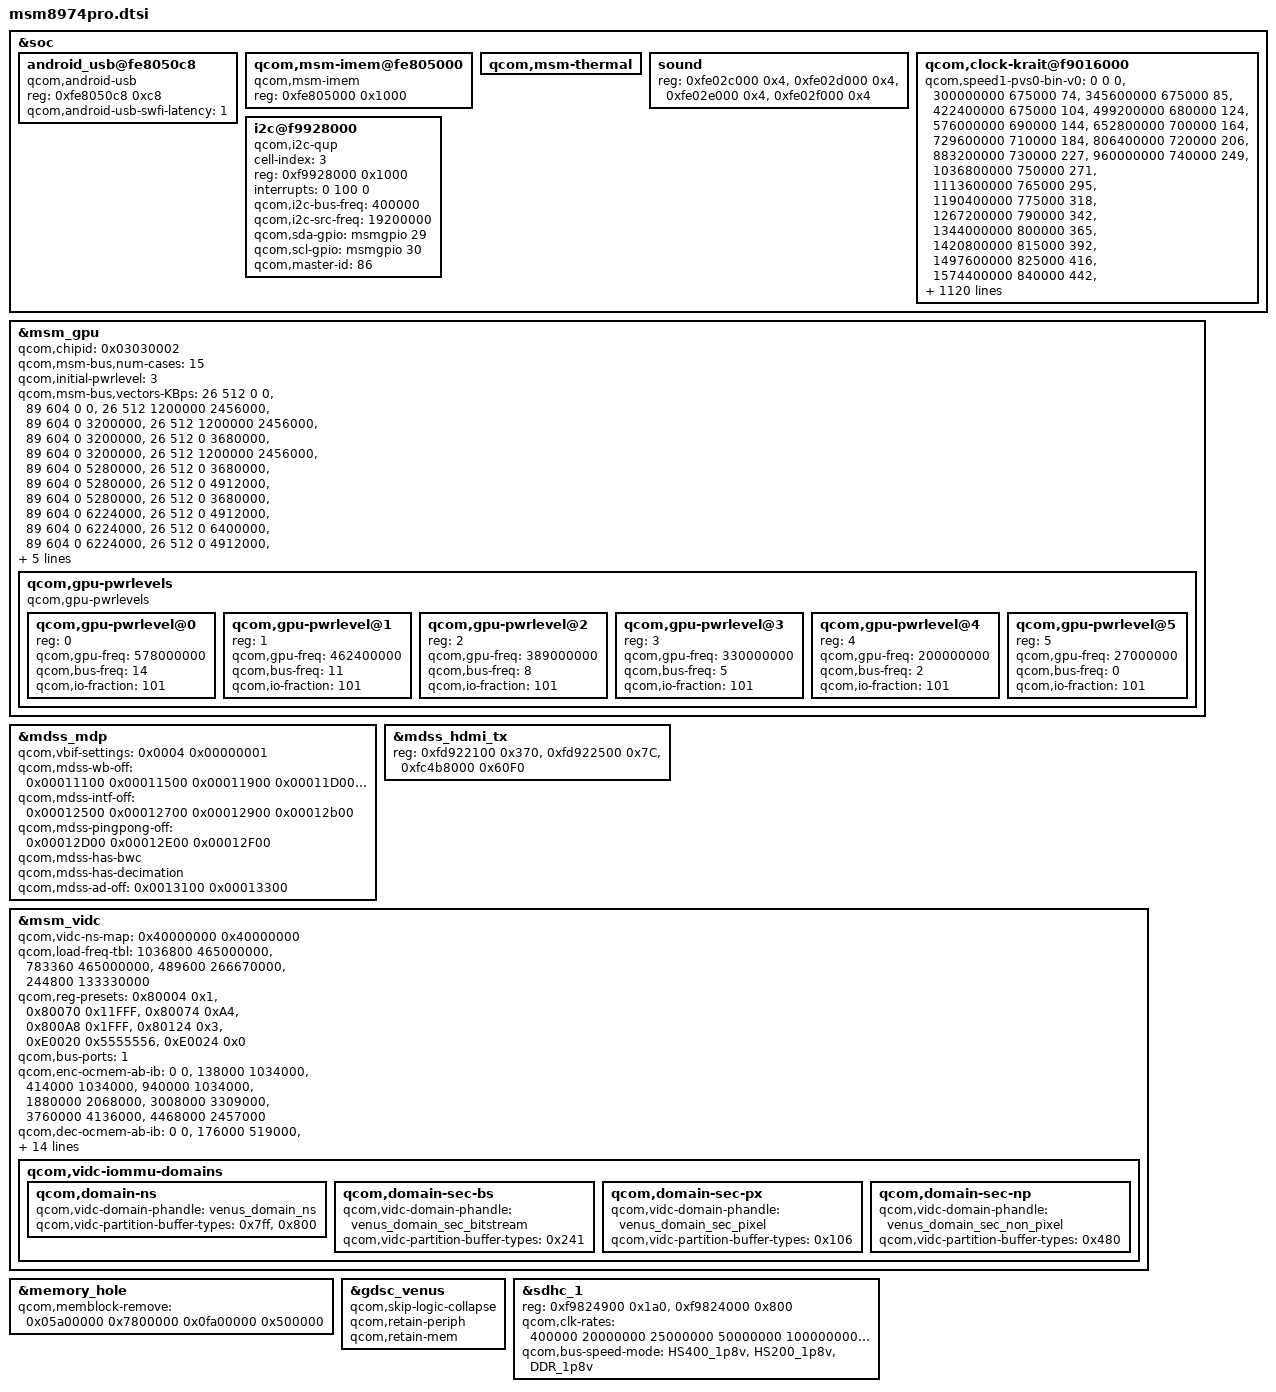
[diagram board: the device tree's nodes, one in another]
/* Copyright (c) 2013-2014, The Linux Foundation. All rights reserved.
 * Copyright (C) 2013 Sony Mobile Communications AB.
 *
 * This program is free software; you can redistribute it and/or modify
 * it under the terms of the GNU General Public License version 2 and
 * only version 2 as published by the Free Software Foundation.
 *
 * This program is distributed in the hope that it will be useful,
 * but WITHOUT ANY WARRANTY; without even the implied warranty of
 * MERCHANTABILITY or FITNESS FOR A PARTICULAR PURPOSE.  See the
 * GNU General Public License for more details.
 */

/*
 * As a general rule, only version-specific property overrides should be placed
 * inside this file. However, device definitions should be placed inside the
 * msm8974.dtsi file.
 */

/include/ "msm8974.dtsi"
/include/ "msm8974-v2-iommu.dtsi"
/include/ "msm8974-v2-iommu-domains.dtsi"
/include/ "msm8974pro-pm.dtsi"
/include/ "msm8974pro-ion.dtsi"

&soc {
	android_usb@fe8050c8 {
		compatible = "qcom,android-usb";
		reg = <0xfe8050c8 0xc8>;
		qcom,android-usb-swfi-latency = <1>;
	};

	qcom,msm-imem@fe805000 {
		compatible = "qcom,msm-imem";
		reg = <0xfe805000 0x1000>; /* Address and size of IMEM */
	};

	qcom,msm-thermal {
		/delete-property/ qcom,pmic-sw-mode-temp;
		/delete-property/ qcom,pmic-sw-mode-temp-hysteresis;
		/delete-property/ qcom,pmic-sw-mode-regs;
	};

	sound {
		reg = <0xfe02c000 0x4>,
		      <0xfe02d000 0x4>,
		      <0xfe02e000 0x4>,
		      <0xfe02f000 0x4>;
		reg-names = "lpaif_pri_mode_muxsel",
			    "lpaif_sec_mode_muxsel",
			    "lpaif_tert_mode_muxsel",
			    "lpaif_quat_mode_muxsel";
	};

	qcom,clock-krait@f9016000 {
		qcom,speed1-pvs0-bin-v0 =
			<          0       0    0 >,
			<  300000000  675000   74 >,
			<  345600000  675000   85 >,
			<  422400000  675000  104 >,
			<  499200000  680000  124 >,
			<  576000000  690000  144 >,
			<  652800000  700000  164 >,
			<  729600000  710000  184 >,
			<  806400000  720000  206 >,
			<  883200000  730000  227 >,
			<  960000000  740000  249 >,
			< 1036800000  750000  271 >,
			< 1113600000  765000  295 >,
			< 1190400000  775000  318 >,
			< 1267200000  790000  342 >,
			< 1344000000  800000  365 >,
			< 1420800000  815000  392 >,
			< 1497600000  825000  416 >,
			< 1574400000  840000  442 >,
			< 1651200000  855000  469 >,
			< 1728000000  870000  497 >,
			< 1804800000  885000  525 >,
			< 1881600000 900000  554 >,
			< 1958400000 915000  583 >,
			< 2035200000 930000  613 >,
			< 2112000000 945000  642 >,
			< 2150400000 960000  663 >,
			< 2188800000 960000  675 >,
			< 2265600000 975000  708 >;

		qcom,speed1-pvs1-bin-v0 =
			<          0       0    0 >,
			<  300000000  675000   74 >,
			<  345600000  675000   85 >,
			<  422400000  675000  104 >,
			<  499200000  675000  124 >,
			<  576000000  675000  144 >,
			<  652800000  685000  164 >,
			<  729600000  695000  184 >,
			<  806400000  705000  206 >,
			<  883200000  715000  227 >,
			<  960000000  725000  249 >,
			< 1036800000  735000  271 >,
			< 1113600000  750000  295 >,
			< 1190400000  760000  318 >,
			< 1267200000  770000  342 >,
			< 1344000000  785000  365 >,
			< 1420800000  795000  392 >,
			< 1497600000  805000  416 >,
			< 1574400000  820000  442 >,
			< 1651200000  835000  469 >,
			< 1728000000  850000  497 >,
			< 1804800000  865000  525 >,
			< 1881600000  880000  554 >,
			< 1958400000  895000  583 >,
			< 2035200000 905000  613 >,
			< 2112000000 920000  642 >,
			< 2150400000 935000  663 >,
			< 2188800000 935000  675 >,
			< 2265600000 950000  708 >;

		qcom,speed1-pvs2-bin-v0 =
			<          0       0    0 >,
			<  300000000  650000   74 >,
			<  345600000  650000   85 >,
			<  422400000  650000  104 >,
			<  499200000  650000  124 >,
			<  576000000  660000  144 >,
			<  652800000  670000  164 >,
			<  729600000  680000  184 >,
			<  806400000  690000  206 >,
			<  883200000  700000  227 >,
			<  960000000  710000  249 >,
			< 1036800000  720000  271 >,
			< 1113600000  730000  295 >,
			< 1190400000  740000  318 >,
			< 1267200000  750000  342 >,
			< 1344000000  765000  365 >,
			< 1420800000  775000  392 >,
			< 1497600000  785000  416 >,
			< 1574400000  800000  442 >,
			< 1651200000  815000  469 >,
			< 1728000000  830000  497 >,
			< 1804800000  845000  525 >,
			< 1881600000  855000  554 >,
			< 1958400000  870000  583 >,
			< 2035200000  880000  613 >,
			< 2112000000  895000  642 >,
			< 2150400000 910000  663 >,
			< 2188800000 910000  675 >,
			< 2265600000 925000  708 >;

		qcom,speed1-pvs3-bin-v0 =
			<          0       0    0 >,
			<  300000000  650000   74 >,
			<  345600000  650000   85 >,
			<  422400000  650000  104 >,
			<  499200000  650000  124 >,
			<  576000000  650000  144 >,
			<  652800000  655000  164 >,
			<  729600000  665000  184 >,
			<  806400000  675000  206 >,
			<  883200000  685000  227 >,
			<  960000000  695000  249 >,
			< 1036800000  705000  271 >,
			< 1113600000  715000  295 >,
			< 1190400000  725000  318 >,
			< 1267200000  735000  342 >,
			< 1344000000  750000  365 >,
			< 1420800000  760000  392 >,
			< 1497600000  770000  416 >,
			< 1574400000  785000  442 >,
			< 1651200000  800000  469 >,
			< 1728000000  810000  497 >,
			< 1804800000  825000  525 >,
			< 1881600000  835000  554 >,
			< 1958400000  845000  583 >,
			< 2035200000  860000  613 >,
			< 2112000000  870000  642 >,
			< 2150400000  885000  663 >,
			< 2188800000  885000  675 >,
			< 2265600000 900000  708 >;

		qcom,speed1-pvs4-bin-v0 =
			<          0       0    0 >,
			<  300000000  650000   74 >,
			<  345600000  650000   85 >,
			<  422400000  650000  104 >,
			<  499200000  650000  124 >,
			<  576000000  650000  144 >,
			<  652800000  650000  164 >,
			<  729600000  655000  184 >,
			<  806400000  665000  206 >,
			<  883200000  675000  227 >,
			<  960000000  685000  249 >,
			< 1036800000  695000  271 >,
			< 1113600000  705000  295 >,
			< 1190400000  715000  318 >,
			< 1267200000  725000  342 >,
			< 1344000000  735000  365 >,
			< 1420800000  745000  392 >,
			< 1497600000  755000  416 >,
			< 1574400000  770000  442 >,
			< 1651200000  785000  469 >,
			< 1728000000  795000  497 >,
			< 1804800000  805000  525 >,
			< 1881600000  815000  554 >,
			< 1958400000  825000  583 >,
			< 2035200000  835000  613 >,
			< 2112000000  850000  642 >,
			< 2150400000  860000  663 >,
			< 2188800000  860000  675 >,
			< 2265600000  875000  708 >;

		qcom,speed1-pvs5-bin-v0 =
			<          0       0    0 >,
			<  300000000  625000   74 >,
			<  345600000  625000   85 >,
			<  422400000  625000  104 >,
			<  499200000  625000  124 >,
			<  576000000  625000  144 >,
			<  652800000  635000  164 >,
			<  729600000  645000  184 >,
			<  806400000  655000  206 >,
			<  883200000  665000  227 >,
			<  960000000  675000  249 >,
			< 1036800000  685000  271 >,
			< 1113600000  695000  295 >,
			< 1190400000  705000  318 >,
			< 1267200000  715000  342 >,
			< 1344000000  725000  365 >,
			< 1420800000  735000  392 >,
			< 1497600000  745000  416 >,
			< 1574400000  755000  442 >,
			< 1651200000  765000  469 >,
			< 1728000000  775000  497 >,
			< 1804800000  785000  525 >,
			< 1881600000  795000  554 >,
			< 1958400000  805000  583 >,
			< 2035200000  815000  613 >,
			< 2112000000  830000  642 >,
			< 2150400000  840000  663 >,
			< 2188800000  840000  675 >,
			< 2265600000  850000  708 >;

		qcom,speed1-pvs6-bin-v0 =
			<          0       0    0 >,
			<  300000000  625000   74 >,
			<  345600000  625000   85 >,
			<  422400000  625000  104 >,
			<  499200000  625000  124 >,
			<  576000000  625000  144 >,
			<  652800000  625000  164 >,
			<  729600000  635000  184 >,
			<  806400000  645000  206 >,
			<  883200000  655000  227 >,
			<  960000000  665000  249 >,
			< 1036800000  675000  271 >,
			< 1113600000  685000  295 >,
			< 1190400000  695000  318 >,
			< 1267200000  705000  342 >,
			< 1344000000  715000  365 >,
			< 1420800000  725000  392 >,
			< 1497600000  735000  416 >,
			< 1574400000  745000  442 >,
			< 1651200000  750000  469 >,
			< 1728000000  760000  497 >,
			< 1804800000  770000  525 >,
			< 1881600000  780000  554 >,
			< 1958400000  790000  583 >,
			< 2035200000  795000  613 >,
			< 2112000000  805000  642 >,
			< 2150400000  815000  663 >,
			< 2188800000  815000  675 >,
			< 2265600000  825000  708 >;

		qcom,speed3-pvs0-bin-v0 =
			<          0       0    0 >,
			<  300000000  700000   76 >,
			<  345600000  700000   87 >,
			<  422400000  700000  106 >,
			<  499200000  700000  125 >,
			<  576000000  700000  145 >,
			<  652800000  710000  165 >,
			<  729600000  720000  186 >,
			<  806400000  730000  208 >,
			<  883200000  740000  229 >,
			<  960000000  750000  251 >,
			< 1036800000  760000  273 >,
			< 1113600000  770000  296 >,
			< 1190400000  780000  319 >,
			< 1267200000  790000  342 >,
			< 1344000000  800000  365 >,
			< 1420800000  810000  390 >,
			< 1497600000  820000  415 >,
			< 1574400000  830000  439 >,
			< 1651200000  845000  465 >,
			< 1728000000  860000  493 >,
			< 1804800000  875000  521 >,
			< 1881600000  890000  549 >,
			< 1958400000 905000  579 >,
			< 2035200000 920000  608 >,
			< 2112000000 935000  638 >,
			< 2150400000 950000  667 >,
			< 2188800000 950000  667 >,
			< 2265600000 965000  700 >,
			< 2342400000 980000  734 >,
			< 2419200000 995000  769 >,
			< 2457600000 1000000  785 >;

		qcom,speed3-pvs1-bin-v0 =
			<          0       0    0 >,
			<  300000000  700000   76 >,
			<  345600000  700000   87 >,
			<  422400000  700000  106 >,
			<  499200000  700000  125 >,
			<  576000000  700000  145 >,
			<  652800000  700000  165 >,
			<  729600000  700000  186 >,
			<  806400000  705000  208 >,
			<  883200000  715000  229 >,
			<  960000000  725000  251 >,
			< 1036800000  735000  273 >,
			< 1113600000  745000  296 >,
			< 1190400000  755000  319 >,
			< 1267200000  765000  342 >,
			< 1344000000  775000  365 >,
			< 1420800000  785000  390 >,
			< 1497600000  795000  415 >,
			< 1574400000  805000  439 >,
			< 1651200000  820000  465 >,
			< 1728000000  835000  493 >,
			< 1804800000  850000  521 >,
			< 1881600000  865000  549 >,
			< 1958400000  880000  579 >,
			< 2035200000  895000  608 >,
			< 2112000000 910000  638 >,
			< 2150400000 925000  667 >,
			< 2188800000 925000  667 >,
			< 2265600000 940000  700 >,
			< 2342400000 955000  734 >,
			< 2419200000 970000  769 >,
			< 2457600000 975000  785 >;

		qcom,speed3-pvs2-bin-v0 =
			<          0       0    0 >,
			<  300000000  675000   76 >,
			<  345600000  675000   87 >,
			<  422400000  675000  106 >,
			<  499200000  675000  125 >,
			<  576000000  675000  145 >,
			<  652800000  675000  165 >,
			<  729600000  675000  186 >,
			<  806400000  680000  208 >,
			<  883200000  690000  229 >,
			<  960000000  700000  251 >,
			< 1036800000  710000  273 >,
			< 1113600000  720000  296 >,
			< 1190400000  730000  319 >,
			< 1267200000  740000  342 >,
			< 1344000000  750000  365 >,
			< 1420800000  760000  390 >,
			< 1497600000  770000  415 >,
			< 1574400000  780000  439 >,
			< 1651200000  795000  465 >,
			< 1728000000  810000  493 >,
			< 1804800000  825000  521 >,
			< 1881600000  840000  549 >,
			< 1958400000  855000  579 >,
			< 2035200000  870000  608 >,
			< 2112000000  885000  638 >,
			< 2150400000 900000  667 >,
			< 2188800000 900000  667 >,
			< 2265600000 915000  700 >,
			< 2342400000 930000  734 >,
			< 2419200000 945000  769 >,
			< 2457600000 950000  785 >;

		qcom,speed3-pvs3-bin-v0 =
			<          0       0    0 >,
			<  300000000  675000   76 >,
			<  345600000  675000   87 >,
			<  422400000  675000  106 >,
			<  499200000  675000  125 >,
			<  576000000  675000  145 >,
			<  652800000  675000  165 >,
			<  729600000  675000  186 >,
			<  806400000  675000  208 >,
			<  883200000  675000  229 >,
			<  960000000  680000  251 >,
			< 1036800000  685000  273 >,
			< 1113600000  695000  296 >,
			< 1190400000  705000  319 >,
			< 1267200000  715000  342 >,
			< 1344000000  725000  365 >,
			< 1420800000  735000  390 >,
			< 1497600000  745000  415 >,
			< 1574400000  755000  439 >,
			< 1651200000  770000  465 >,
			< 1728000000  785000  493 >,
			< 1804800000  800000  521 >,
			< 1881600000  815000  549 >,
			< 1958400000  830000  579 >,
			< 2035200000  845000  608 >,
			< 2112000000  860000  638 >,
			< 2150400000  875000  667 >,
			< 2188800000  875000  667 >,
			< 2265600000  890000  700 >,
			< 2342400000 905000  734 >,
			< 2419200000 920000  769 >,
			< 2457600000 925000  785 >;

		qcom,speed3-pvs4-bin-v0 =
			<          0       0    0 >,
			<  300000000  675000   76 >,
			<  345600000  675000   87 >,
			<  422400000  675000  106 >,
			<  499200000  675000  125 >,
			<  576000000  675000  145 >,
			<  652800000  675000  165 >,
			<  729600000  675000  186 >,
			<  806400000  675000  208 >,
			<  883200000  675000  229 >,
			<  960000000  675000  251 >,
			< 1036800000  675000  273 >,
			< 1113600000  675000  296 >,
			< 1190400000  680000  319 >,
			< 1267200000  690000  342 >,
			< 1344000000  700000  365 >,
			< 1420800000  710000  390 >,
			< 1497600000  720000  415 >,
			< 1574400000  730000  439 >,
			< 1651200000  745000  465 >,
			< 1728000000  760000  493 >,
			< 1804800000  775000  521 >,
			< 1881600000  790000  549 >,
			< 1958400000  805000  579 >,
			< 2035200000  820000  608 >,
			< 2112000000  835000  638 >,
			< 2150400000  850000  667 >,
			< 2188800000  850000  667 >,
			< 2265600000  865000  700 >,
			< 2342400000  880000  734 >,
			< 2419200000  895000  769 >,
			< 2457600000 900000  785 >;

		qcom,speed3-pvs5-bin-v0 =
			<          0       0    0 >,
			<  300000000  650000   76 >,
			<  345600000  650000   87 >,
			<  422400000  650000  106 >,
			<  499200000  650000  125 >,
			<  576000000  650000  145 >,
			<  652800000  650000  165 >,
			<  729600000  650000  186 >,
			<  806400000  650000  208 >,
			<  883200000  650000  229 >,
			<  960000000  650000  251 >,
			< 1036800000  650000  273 >,
			< 1113600000  650000  296 >,
			< 1190400000  660000  319 >,
			< 1267200000  670000  342 >,
			< 1344000000  680000  365 >,
			< 1420800000  690000  390 >,
			< 1497600000  700000  415 >,
			< 1574400000  710000  439 >,
			< 1651200000  720000  465 >,
			< 1728000000  735000  493 >,
			< 1804800000  750000  521 >,
			< 1881600000  765000  549 >,
			< 1958400000  780000  579 >,
			< 2035200000  795000  608 >,
			< 2112000000  810000  638 >,
			< 2150400000  825000  667 >,
			< 2188800000  825000  667 >,
			< 2265600000  840000  700 >,
			< 2342400000  855000  734 >,
			< 2419200000  870000  769 >,
			< 2457600000  875000  785 >;

		qcom,speed3-pvs6-bin-v0 =
			<          0       0    0 >,
			<  300000000  650000   76 >,
			<  345600000  650000   87 >,
			<  422400000  650000  106 >,
			<  499200000  650000  125 >,
			<  576000000  650000  145 >,
			<  652800000  650000  165 >,
			<  729600000  650000  186 >,
			<  806400000  650000  208 >,
			<  883200000  650000  229 >,
			<  960000000  650000  251 >,
			< 1036800000  650000  273 >,
			< 1113600000  650000  296 >,
			< 1190400000  650000  319 >,
			< 1267200000  655000  342 >,
			< 1344000000  665000  365 >,
			< 1420800000  675000  390 >,
			< 1497600000  685000  415 >,
			< 1574400000  695000  439 >,
			< 1651200000  705000  465 >,
			< 1728000000  715000  493 >,
			< 1804800000  725000  521 >,
			< 1881600000  740000  549 >,
			< 1958400000  755000  579 >,
			< 2035200000  770000  608 >,
			< 2112000000  785000  638 >,
			< 2150400000  800000  667 >,
			< 2188800000  800000  667 >,
			< 2265600000  815000  700 >,
			< 2342400000  830000  734 >,
			< 2419200000  845000  769 >,
			< 2457600000  850000  785 >;

		qcom,speed1-pvs0-bin-v1 =
			<          0       0    0 >,
			<  300000000  700000   76 >,
			<  345600000  710000   87 >,
			<  422400000  720000  108 >,
			<  499200000  730000  129 >,
			<  576000000  740000  150 >,
			<  652800000  750000  171 >,
			<  729600000  760000  193 >,
			<  806400000  770000  215 >,
			<  883200000  780000  237 >,
			<  960000000  790000  260 >,
			< 1036800000  800000  282 >,
			< 1113600000  810000  306 >,
			< 1190400000  820000  330 >,
			< 1267200000  830000  354 >,
			< 1344000000  840000  378 >,
			< 1420800000  855000  404 >,
			< 1497600000  870000  431 >,
			< 1574400000  885000  458 >,
			< 1651200000 900000  486 >,
			< 1728000000 915000  515 >,
			< 1804800000 930000  543 >,
			< 1881600000 945000  572 >,
			< 1958400000 960000  604 >,
			< 2035200000 975000  636 >,
			< 2112000000 990000  669 >,
			< 2150400000 1005000  703 >,
			< 2188800000 1005000  703 >,
			< 2265600000 1020000  738 >;

		qcom,speed1-pvs1-bin-v1 =
			<          0       0    0 >,
			<  300000000  700000   76 >,
			<  345600000  700000   87 >,
			<  422400000  710000  108 >,
			<  499200000  720000  129 >,
			<  576000000  730000  150 >,
			<  652800000  740000  171 >,
			<  729600000  750000  193 >,
			<  806400000  760000  215 >,
			<  883200000  770000  237 >,
			<  960000000  780000  260 >,
			< 1036800000  790000  282 >,
			< 1113600000  800000  306 >,
			< 1190400000  810000  330 >,
			< 1267200000  820000  354 >,
			< 1344000000  830000  378 >,
			< 1420800000  845000  404 >,
			< 1497600000  860000  431 >,
			< 1574400000  875000  458 >,
			< 1651200000  890000  486 >,
			< 1728000000 905000  515 >,
			< 1804800000 920000  543 >,
			< 1881600000 935000  572 >,
			< 1958400000 950000  604 >,
			< 2035200000 965000  636 >,
			< 2112000000 980000  669 >,
			< 2150400000 995000  703 >,
			< 2188800000 995000  703 >,
			< 2265600000 1010000  738 >;

		qcom,speed1-pvs2-bin-v1 =
			<          0       0    0 >,
			<  300000000  700000   76 >,
			<  345600000  700000   87 >,
			<  422400000  700000  108 >,
			<  499200000  710000  129 >,
			<  576000000  720000  150 >,
			<  652800000  730000  171 >,
			<  729600000  740000  193 >,
			<  806400000  750000  215 >,
			<  883200000  760000  237 >,
			<  960000000  770000  260 >,
			< 1036800000  780000  282 >,
			< 1113600000  790000  306 >,
			< 1190400000  800000  330 >,
			< 1267200000  810000  354 >,
			< 1344000000  820000  378 >,
			< 1420800000  835000  404 >,
			< 1497600000  850000  431 >,
			< 1574400000  865000  458 >,
			< 1651200000  880000  486 >,
			< 1728000000  895000  515 >,
			< 1804800000 910000  543 >,
			< 1881600000 925000  572 >,
			< 1958400000 940000  604 >,
			< 2035200000 955000  636 >,
			< 2112000000 970000  669 >,
			< 2150400000 985000  703 >,
			< 2188800000 985000  703 >,
			< 2265600000 1000000  738 >;

		qcom,speed1-pvs3-bin-v1 =
			<          0       0    0 >,
			<  300000000  700000   76 >,
			<  345600000  700000   87 >,
			<  422400000  700000  108 >,
			<  499200000  700000  129 >,
			<  576000000  710000  150 >,
			<  652800000  720000  171 >,
			<  729600000  730000  193 >,
			<  806400000  740000  215 >,
			<  883200000  750000  237 >,
			<  960000000  760000  260 >,
			< 1036800000  770000  282 >,
			< 1113600000  780000  306 >,
			< 1190400000  790000  330 >,
			< 1267200000  800000  354 >,
			< 1344000000  810000  378 >,
			< 1420800000  825000  404 >,
			< 1497600000  840000  431 >,
			< 1574400000  855000  458 >,
			< 1651200000  870000  486 >,
			< 1728000000  885000  515 >,
			< 1804800000 900000  543 >,
			< 1881600000 915000  572 >,
			< 1958400000 930000  604 >,
			< 2035200000 945000  636 >,
			< 2112000000 960000  669 >,
			< 2150400000 975000  703 >,
			< 2188800000 975000  703 >,
			< 2265600000 990000  738 >;

		qcom,speed1-pvs4-bin-v1 =
			<          0       0    0 >,
			<  300000000  700000   76 >,
			<  345600000  700000   87 >,
			<  422400000  700000  108 >,
			<  499200000  700000  129 >,
			<  576000000  700000  150 >,
			<  652800000  710000  171 >,
			<  729600000  720000  193 >,
			<  806400000  730000  215 >,
			<  883200000  740000  237 >,
			<  960000000  750000  260 >,
			< 1036800000  760000  282 >,
			< 1113600000  770000  306 >,
			< 1190400000  780000  330 >,
			< 1267200000  790000  354 >,
			< 1344000000  800000  378 >,
			< 1420800000  815000  404 >,
			< 1497600000  830000  431 >,
			< 1574400000  845000  458 >,
			< 1651200000  860000  486 >,
			< 1728000000  875000  515 >,
			< 1804800000  890000  543 >,
			< 1881600000 905000  572 >,
			< 1958400000 920000  604 >,
			< 2035200000 935000  636 >,
			< 2112000000 950000  669 >,
			< 2150400000 965000  703 >,
			< 2188800000 965000  703 >,
			< 2265600000 980000  738 >;

		qcom,speed1-pvs5-bin-v1 =
			<          0       0    0 >,
			<  300000000  700000   76 >,
			<  345600000  700000   87 >,
			<  422400000  700000  108 >,
			<  499200000  700000  129 >,
			<  576000000  700000  150 >,
			<  652800000  700000  171 >,
			<  729600000  710000  193 >,
			<  806400000  720000  215 >,
			<  883200000  730000  237 >,
			<  960000000  740000  260 >,
			< 1036800000  750000  282 >,
			< 1113600000  760000  306 >,
			< 1190400000  770000  330 >,
			< 1267200000  780000  354 >,
			< 1344000000  790000  378 >,
			< 1420800000  805000  404 >,
			< 1497600000  820000  431 >,
			< 1574400000  835000  458 >,
			< 1651200000  850000  486 >,
			< 1728000000  865000  515 >,
			< 1804800000  880000  543 >,
			< 1881600000  895000  572 >,
			< 1958400000 910000  604 >,
			< 2035200000 925000  636 >,
			< 2112000000 940000  669 >,
			< 2150400000 955000  703 >,
			< 2188800000 955000  703 >,
			< 2265600000 970000  738 >;

		qcom,speed1-pvs6-bin-v1 =
			<          0       0    0 >,
			<  300000000  675000   76 >,
			<  345600000  675000   87 >,
			<  422400000  675000  108 >,
			<  499200000  675000  129 >,
			<  576000000  685000  150 >,
			<  652800000  695000  171 >,
			<  729600000  705000  193 >,
			<  806400000  715000  215 >,
			<  883200000  725000  237 >,
			<  960000000  735000  260 >,
			< 1036800000  745000  282 >,
			< 1113600000  755000  306 >,
			< 1190400000  765000  330 >,
			< 1267200000  775000  354 >,
			< 1344000000  785000  378 >,
			< 1420800000  795000  404 >,
			< 1497600000  810000  431 >,
			< 1574400000  825000  458 >,
			< 1651200000  840000  486 >,
			< 1728000000  855000  515 >,
			< 1804800000  870000  543 >,
			< 1881600000  885000  572 >,
			< 1958400000 900000  604 >,
			< 2035200000 915000  636 >,
			< 2112000000 930000  669 >,
			< 2150400000 945000  703 >,
			< 2188800000 945000  703 >,
			< 2265600000 960000  738 >;

		qcom,speed1-pvs7-bin-v1 =
			<          0       0    0 >,
			<  300000000  675000   76 >,
			<  345600000  675000   87 >,
			<  422400000  675000  108 >,
			<  499200000  675000  129 >,
			<  576000000  680000  150 >,
			<  652800000  690000  171 >,
			<  729600000  700000  193 >,
			<  806400000  710000  215 >,
			<  883200000  720000  237 >,
			<  960000000  730000  260 >,
			< 1036800000  740000  282 >,
			< 1113600000  750000  306 >,
			< 1190400000  760000  330 >,
			< 1267200000  770000  354 >,
			< 1344000000  780000  378 >,
			< 1420800000  790000  404 >,
			< 1497600000  800000  431 >,
			< 1574400000  815000  458 >,
			< 1651200000  830000  486 >,
			< 1728000000  845000  515 >,
			< 1804800000  860000  543 >,
			< 1881600000  875000  572 >,
			< 1958400000  890000  604 >,
			< 2035200000 905000  636 >,
			< 2112000000 920000  669 >,
			< 2150400000 935000  703 >,
			< 2188800000 935000  703 >,
			< 2265600000 950000  738 >;

		qcom,speed1-pvs8-bin-v1 =
			<          0       0    0 >,
			<  300000000  675000   76 >,
			<  345600000  675000   87 >,
			<  422400000  675000  108 >,
			<  499200000  675000  129 >,
			<  576000000  675000  150 >,
			<  652800000  680000  171 >,
			<  729600000  690000  193 >,
			<  806400000  700000  215 >,
			<  883200000  710000  237 >,
			<  960000000  720000  260 >,
			< 1036800000  730000  282 >,
			< 1113600000  740000  306 >,
			< 1190400000  750000  330 >,
			< 1267200000  760000  354 >,
			< 1344000000  770000  378 >,
			< 1420800000  780000  404 >,
			< 1497600000  790000  431 >,
			< 1574400000  805000  458 >,
			< 1651200000  820000  486 >,
			< 1728000000  835000  515 >,
			< 1804800000  850000  543 >,
			< 1881600000  865000  572 >,
			< 1958400000  880000  604 >,
			< 2035200000  895000  636 >,
			< 2112000000 910000  669 >,
			< 2150400000 925000  703 >,
			< 2188800000 925000  703 >,
			< 2265600000 940000  738 >;

		qcom,speed1-pvs9-bin-v1 =
			<          0       0    0 >,
			<  300000000  675000   76 >,
			<  345600000  675000   87 >,
			<  422400000  675000  108 >,
			<  499200000  675000  129 >,
			<  576000000  675000  150 >,
			<  652800000  675000  171 >,
			<  729600000  685000  193 >,
			<  806400000  695000  215 >,
			<  883200000  705000  237 >,
			<  960000000  715000  260 >,
			< 1036800000  725000  282 >,
			< 1113600000  735000  306 >,
			< 1190400000  745000  330 >,
			< 1267200000  755000  354 >,
			< 1344000000  765000  378 >,
			< 1420800000  775000  404 >,
			< 1497600000  785000  431 >,
			< 1574400000  795000  458 >,
			< 1651200000  810000  486 >,
			< 1728000000  825000  515 >,
			< 1804800000  840000  543 >,
			< 1881600000  855000  572 >,
			< 1958400000  870000  604 >,
			< 2035200000  885000  636 >,
			< 2112000000 900000  669 >,
			< 2150400000 915000  703 >,
			< 2188800000 915000  703 >,
			< 2265600000 930000  738 >;

		qcom,speed1-pvs10-bin-v1 =
			<          0       0    0 >,
			<  300000000  675000   76 >,
			<  345600000  675000   87 >,
			<  422400000  675000  108 >,
			<  499200000  675000  129 >,
			<  576000000  675000  150 >,
			<  652800000  675000  171 >,
			<  729600000  680000  193 >,
			<  806400000  690000  215 >,
			<  883200000  700000  237 >,
			<  960000000  710000  260 >,
			< 1036800000  720000  282 >,
			< 1113600000  730000  306 >,
			< 1190400000  740000  330 >,
			< 1267200000  750000  354 >,
			< 1344000000  760000  378 >,
			< 1420800000  770000  404 >,
			< 1497600000  780000  431 >,
			< 1574400000  790000  458 >,
			< 1651200000  800000  486 >,
			< 1728000000  815000  515 >,
			< 1804800000  830000  543 >,
			< 1881600000  845000  572 >,
			< 1958400000  860000  604 >,
			< 2035200000  875000  636 >,
			< 2112000000  890000  669 >,
			< 2150400000 905000  703 >,
			< 2188800000 905000  703 >,
			< 2265600000 920000  738 >;

		qcom,speed1-pvs11-bin-v1 =
			<          0       0    0 >,
			<  300000000  675000   76 >,
			<  345600000  675000   87 >,
			<  422400000  675000  108 >,
			<  499200000  675000  129 >,
			<  576000000  675000  150 >,
			<  652800000  675000  171 >,
			<  729600000  675000  193 >,
			<  806400000  685000  215 >,
			<  883200000  695000  237 >,
			<  960000000  705000  260 >,
			< 1036800000  715000  282 >,
			< 1113600000  725000  306 >,
			< 1190400000  735000  330 >,
			< 1267200000  745000  354 >,
			< 1344000000  755000  378 >,
			< 1420800000  765000  404 >,
			< 1497600000  775000  431 >,
			< 1574400000  785000  458 >,
			< 1651200000  795000  486 >,
			< 1728000000  805000  515 >,
			< 1804800000  820000  543 >,
			< 1881600000  835000  572 >,
			< 1958400000  850000  604 >,
			< 2035200000  865000  636 >,
			< 2112000000  880000  669 >,
			< 2150400000  895000  703 >,
			< 2188800000  895000  703 >,
			< 2265600000 910000  738 >;

		qcom,speed1-pvs12-bin-v1 =
			<          0       0    0 >,
			<  300000000  675000   76 >,
			<  345600000  675000   87 >,
			<  422400000  675000  108 >,
			<  499200000  675000  129 >,
			<  576000000  675000  150 >,
			<  652800000  675000  171 >,
			<  729600000  675000  193 >,
			<  806400000  680000  215 >,
			<  883200000  690000  237 >,
			<  960000000  700000  260 >,
			< 1036800000  710000  282 >,
			< 1113600000  720000  306 >,
			< 1190400000  730000  330 >,
			< 1267200000  740000  354 >,
			< 1344000000  750000  378 >,
			< 1420800000  760000  404 >,
			< 1497600000  770000  431 >,
			< 1574400000  780000  458 >,
			< 1651200000  790000  486 >,
			< 1728000000  800000  515 >,
			< 1804800000  810000  543 >,
			< 1881600000  825000  572 >,
			< 1958400000  840000  604 >,
			< 2035200000  855000  636 >,
			< 2112000000  870000  669 >,
			< 2150400000  885000  703 >,
			< 2188800000  885000  703 >,
			< 2265600000 900000  738 >;

		qcom,speed1-pvs13-bin-v1 =
			<          0       0    0 >,
			<  300000000  675000   76 >,
			<  345600000  675000   87 >,
			<  422400000  675000  108 >,
			<  499200000  675000  129 >,
			<  576000000  675000  150 >,
			<  652800000  675000  171 >,
			<  729600000  675000  193 >,
			<  806400000  675000  215 >,
			<  883200000  685000  237 >,
			<  960000000  695000  260 >,
			< 1036800000  705000  282 >,
			< 1113600000  715000  306 >,
			< 1190400000  725000  330 >,
			< 1267200000  735000  354 >,
			< 1344000000  745000  378 >,
			< 1420800000  755000  404 >,
			< 1497600000  765000  431 >,
			< 1574400000  775000  458 >,
			< 1651200000  785000  486 >,
			< 1728000000  795000  515 >,
			< 1804800000  805000  543 >,
			< 1881600000  815000  572 >,
			< 1958400000  830000  604 >,
			< 2035200000  845000  636 >,
			< 2112000000  860000  669 >,
			< 2150400000  875000  703 >,
			< 2188800000  875000  703 >,
			< 2265600000  890000  738 >;

		qcom,speed1-pvs14-bin-v1 =
			<          0       0    0 >,
			<  300000000  650000   76 >,
			<  345600000  650000   87 >,
			<  422400000  650000  108 >,
			<  499200000  650000  129 >,
			<  576000000  650000  150 >,
			<  652800000  650000  171 >,
			<  729600000  660000  193 >,
			<  806400000  670000  215 >,
			<  883200000  680000  237 >,
			<  960000000  690000  260 >,
			< 1036800000  700000  282 >,
			< 1113600000  710000  306 >,
			< 1190400000  720000  330 >,
			< 1267200000  730000  354 >,
			< 1344000000  740000  378 >,
			< 1420800000  750000  404 >,
			< 1497600000  760000  431 >,
			< 1574400000  770000  458 >,
			< 1651200000  780000  486 >,
			< 1728000000  790000  515 >,
			< 1804800000  800000  543 >,
			< 1881600000  810000  572 >,
			< 1958400000  820000  604 >,
			< 2035200000  835000  636 >,
			< 2112000000  850000  669 >,
			< 2150400000  865000  703 >,
			< 2188800000  865000  703 >,
			< 2265600000  880000  738 >;

		qcom,speed1-pvs15-bin-v1 =
			<          0       0    0 >,
			<  300000000  650000   76 >,
			<  345600000  650000   87 >,
			<  422400000  650000  108 >,
			<  499200000  650000  129 >,
			<  576000000  650000  150 >,
			<  652800000  650000  171 >,
			<  729600000  655000  193 >,
			<  806400000  665000  215 >,
			<  883200000  675000  237 >,
			<  960000000  685000  260 >,
			< 1036800000  695000  282 >,
			< 1113600000  705000  306 >,
			< 1190400000  715000  330 >,
			< 1267200000  725000  354 >,
			< 1344000000  735000  378 >,
			< 1420800000  745000  404 >,
			< 1497600000  755000  431 >,
			< 1574400000  765000  458 >,
			< 1651200000  775000  486 >,
			< 1728000000  785000  515 >,
			< 1804800000  795000  543 >,
			< 1881600000  805000  572 >,
			< 1958400000  815000  604 >,
			< 2035200000  825000  636 >,
			< 2112000000  840000  669 >,
			< 2150400000  855000  703 >,
			< 2188800000  855000  703 >,
			< 2265600000  870000  738 >;

		qcom,speed3-pvs0-bin-v1 =
			<          0       0    0 >,
			<  300000000  700000   76 >,
			<  345600000  700000   87 >,
			<  422400000  700000  106 >,
			<  499200000  710000  126 >,
			<  576000000  720000  147 >,
			<  652800000  730000  168 >,
			<  729600000  740000  189 >,
			<  806400000  750000  211 >,
			<  883200000  760000  233 >,
			<  960000000  770000  256 >,
			< 1036800000  780000  278 >,
			< 1113600000  790000  301 >,
			< 1190400000  800000  324 >,
			< 1267200000  810000  348 >,
			< 1344000000  820000  372 >,
			< 1420800000  830000  396 >,
			< 1497600000  840000  421 >,
			< 1574400000  850000  446 >,
			< 1651200000  865000  473 >,
			< 1728000000  880000  501 >,
			< 1804800000  895000  529 >,
			< 1881600000 910000  558 >,
			< 1958400000 925000  588 >,
			< 2035200000 940000  617 >,
			< 2112000000 955000  649 >,
			< 2150400000 970000  682 >,
			< 2188800000 970000  682 >,
			< 2265600000 985000  716 >,
			< 2342400000 1000000  751 >,
			< 2419200000 1015000  786 >,
			< 2457600000 1020000  802 >;

		qcom,speed3-pvs1-bin-v1 =
			<          0       0    0 >,
			<  300000000  700000   76 >,
			<  345600000  700000   87 >,
			<  422400000  700000  106 >,
			<  499200000  700000  126 >,
			<  576000000  710000  147 >,
			<  652800000  720000  168 >,
			<  729600000  730000  189 >,
			<  806400000  740000  211 >,
			<  883200000  750000  233 >,
			<  960000000  760000  256 >,
			< 1036800000  770000  278 >,
			< 1113600000  780000  301 >,
			< 1190400000  790000  324 >,
			< 1267200000  800000  348 >,
			< 1344000000  810000  372 >,
			< 1420800000  820000  396 >,
			< 1497600000  830000  421 >,
			< 1574400000  840000  446 >,
			< 1651200000  855000  473 >,
			< 1728000000  870000  501 >,
			< 1804800000  885000  529 >,
			< 1881600000 900000  558 >,
			< 1958400000 915000  588 >,
			< 2035200000 930000  617 >,
			< 2112000000 945000  649 >,
			< 2150400000 960000  682 >,
			< 2188800000 960000  682 >,
			< 2265600000 975000  716 >,
			< 2342400000 990000  751 >,
			< 2419200000 1005000  786 >,
			< 2457600000 1010000  802 >;

		qcom,speed3-pvs2-bin-v1 =
			<          0       0    0 >,
			<  300000000  700000   76 >,
			<  345600000  700000   87 >,
			<  422400000  700000  106 >,
			<  499200000  700000  126 >,
			<  576000000  700000  147 >,
			<  652800000  710000  168 >,
			<  729600000  720000  189 >,
			<  806400000  730000  211 >,
			<  883200000  740000  233 >,
			<  960000000  750000  256 >,
			< 1036800000  760000  278 >,
			< 1113600000  770000  301 >,
			< 1190400000  780000  324 >,
			< 1267200000  790000  348 >,
			< 1344000000  800000  372 >,
			< 1420800000  810000  396 >,
			< 1497600000  820000  421 >,
			< 1574400000  830000  446 >,
			< 1651200000  845000  473 >,
			< 1728000000  860000  501 >,
			< 1804800000  875000  529 >,
			< 1881600000  890000  558 >,
			< 1958400000 905000  588 >,
			< 2035200000 920000  617 >,
			< 2112000000 935000  649 >,
			< 2150400000 950000  682 >,
			< 2188800000 950000  682 >,
			< 2265600000 965000  716 >,
			< 2342400000 980000  751 >,
			< 2419200000 995000  786 >,
			< 2457600000 1000000  802 >;

		qcom,speed3-pvs3-bin-v1 =
			<          0       0    0 >,
			<  300000000  700000   76 >,
			<  345600000  700000   87 >,
			<  422400000  700000  106 >,
			<  499200000  700000  126 >,
			<  576000000  700000  147 >,
			<  652800000  700000  168 >,
			<  729600000  710000  189 >,
			<  806400000  720000  211 >,
			<  883200000  730000  233 >,
			<  960000000  740000  256 >,
			< 1036800000  750000  278 >,
			< 1113600000  760000  301 >,
			< 1190400000  770000  324 >,
			< 1267200000  780000  348 >,
			< 1344000000  790000  372 >,
			< 1420800000  800000  396 >,
			< 1497600000  810000  421 >,
			< 1574400000  820000  446 >,
			< 1651200000  835000  473 >,
			< 1728000000  850000  501 >,
			< 1804800000  865000  529 >,
			< 1881600000  880000  558 >,
			< 1958400000  895000  588 >,
			< 2035200000 910000  617 >,
			< 2112000000 925000  649 >,
			< 2150400000 940000  682 >,
			< 2188800000 940000  682 >,
			< 2265600000 955000  716 >,
			< 2342400000 970000  751 >,
			< 2419200000 985000  786 >,
			< 2457600000 990000  802 >;

		qcom,speed3-pvs4-bin-v1 =
			<          0       0    0 >,
			<  300000000  700000   76 >,
			<  345600000  700000   87 >,
			<  422400000  700000  106 >,
			<  499200000  700000  126 >,
			<  576000000  700000  147 >,
			<  652800000  700000  168 >,
			<  729600000  700000  189 >,
			<  806400000  710000  211 >,
			<  883200000  720000  233 >,
			<  960000000  730000  256 >,
			< 1036800000  740000  278 >,
			< 1113600000  750000  301 >,
			< 1190400000  760000  324 >,
			< 1267200000  770000  348 >,
			< 1344000000  780000  372 >,
			< 1420800000  790000  396 >,
			< 1497600000  800000  421 >,
			< 1574400000  810000  446 >,
			< 1651200000  825000  473 >,
			< 1728000000  840000  501 >,
			< 1804800000  855000  529 >,
			< 1881600000  870000  558 >,
			< 1958400000  885000  588 >,
			< 2035200000 900000  617 >,
			< 2112000000 915000  649 >,
			< 2150400000 930000  682 >,
			< 2188800000 930000  682 >,
			< 2265600000 945000  716 >,
			< 2342400000 960000  751 >,
			< 2419200000 975000  786 >,
			< 2457600000 980000  802 >;

		qcom,speed3-pvs5-bin-v1 =
			<          0       0    0 >,
			<  300000000  700000   76 >,
			<  345600000  700000   87 >,
			<  422400000  700000  106 >,
			<  499200000  700000  126 >,
			<  576000000  700000  147 >,
			<  652800000  700000  168 >,
			<  729600000  700000  189 >,
			<  806400000  700000  211 >,
			<  883200000  710000  233 >,
			<  960000000  720000  256 >,
			< 1036800000  730000  278 >,
			< 1113600000  740000  301 >,
			< 1190400000  750000  324 >,
			< 1267200000  760000  348 >,
			< 1344000000  770000  372 >,
			< 1420800000  780000  396 >,
			< 1497600000  790000  421 >,
			< 1574400000  800000  446 >,
			< 1651200000  815000  473 >,
			< 1728000000  830000  501 >,
			< 1804800000  845000  529 >,
			< 1881600000  860000  558 >,
			< 1958400000  875000  588 >,
			< 2035200000  890000  617 >,
			< 2112000000 905000  649 >,
			< 2150400000 920000  682 >,
			< 2188800000 920000  682 >,
			< 2265600000 935000  716 >,
			< 2342400000 950000  751 >,
			< 2419200000 965000  786 >,
			< 2457600000 970000  802 >;

		qcom,speed3-pvs6-bin-v1 =
			<          0       0    0 >,
			<  300000000  675000   76 >,
			<  345600000  675000   87 >,
			<  422400000  675000  106 >,
			<  499200000  675000  126 >,
			<  576000000  675000  147 >,
			<  652800000  675000  168 >,
			<  729600000  680000  189 >,
			<  806400000  690000  211 >,
			<  883200000  700000  233 >,
			<  960000000  710000  256 >,
			< 1036800000  720000  278 >,
			< 1113600000  730000  301 >,
			< 1190400000  740000  324 >,
			< 1267200000  750000  348 >,
			< 1344000000  760000  372 >,
			< 1420800000  770000  396 >,
			< 1497600000  780000  421 >,
			< 1574400000  790000  446 >,
			< 1651200000  805000  473 >,
			< 1728000000  820000  501 >,
			< 1804800000  835000  529 >,
			< 1881600000  850000  558 >,
			< 1958400000  865000  588 >,
			< 2035200000  880000  617 >,
			< 2112000000  895000  649 >,
			< 2150400000 910000  682 >,
			< 2188800000 910000  682 >,
			< 2265600000 925000  716 >,
			< 2342400000 940000  751 >,
			< 2419200000 955000  786 >,
			< 2457600000 960000  802 >;

		qcom,speed3-pvs7-bin-v1 =
			<          0       0    0 >,
			<  300000000  675000   76 >,
			<  345600000  675000   87 >,
			<  422400000  675000  106 >,
			<  499200000  675000  126 >,
			<  576000000  675000  147 >,
			<  652800000  675000  168 >,
			<  729600000  680000  189 >,
			<  806400000  685000  211 >,
			<  883200000  695000  233 >,
			<  960000000  705000  256 >,
			< 1036800000  715000  278 >,
			< 1113600000  725000  301 >,
			< 1190400000  735000  324 >,
			< 1267200000  745000  348 >,
			< 1344000000  755000  372 >,
			< 1420800000  765000  396 >,
			< 1497600000  775000  421 >,
			< 1574400000  785000  446 >,
			< 1651200000  795000  473 >,
			< 1728000000  810000  501 >,
			< 1804800000  825000  529 >,
			< 1881600000  840000  558 >,
			< 1958400000  855000  588 >,
			< 2035200000  870000  617 >,
			< 2112000000  885000  649 >,
			< 2150400000 900000  682 >,
			< 2188800000 900000  682 >,
			< 2265600000 915000  716 >,
			< 2342400000 930000  751 >,
			< 2419200000 945000  786 >,
			< 2457600000 950000  802 >;

		qcom,speed3-pvs8-bin-v1 =
			<          0       0    0 >,
			<  300000000  675000   76 >,
			<  345600000  675000   87 >,
			<  422400000  675000  106 >,
			<  499200000  675000  126 >,
			<  576000000  675000  147 >,
			<  652800000  675000  168 >,
			<  729600000  675000  189 >,
			<  806400000  680000  211 >,
			<  883200000  685000  233 >,
			<  960000000  695000  256 >,
			< 1036800000  705000  278 >,
			< 1113600000  715000  301 >,
			< 1190400000  725000  324 >,
			< 1267200000  735000  348 >,
			< 1344000000  745000  372 >,
			< 1420800000  755000  396 >,
			< 1497600000  765000  421 >,
			< 1574400000  775000  446 >,
			< 1651200000  785000  473 >,
			< 1728000000  800000  501 >,
			< 1804800000  815000  529 >,
			< 1881600000  830000  558 >,
			< 1958400000  845000  588 >,
			< 2035200000  860000  617 >,
			< 2112000000  875000  649 >,
			< 2150400000  890000  682 >,
			< 2188800000  890000  682 >,
			< 2265600000 905000  716 >,
			< 2342400000 920000  751 >,
			< 2419200000 935000  786 >,
			< 2457600000 940000  802 >;

		qcom,speed3-pvs9-bin-v1 =
			<          0       0    0 >,
			<  300000000  675000   76 >,
			<  345600000  675000   87 >,
			<  422400000  675000  106 >,
			<  499200000  675000  126 >,
			<  576000000  675000  147 >,
			<  652800000  675000  168 >,
			<  729600000  675000  189 >,
			<  806400000  675000  211 >,
			<  883200000  680000  233 >,
			<  960000000  690000  256 >,
			< 1036800000  700000  278 >,
			< 1113600000  710000  301 >,
			< 1190400000  720000  324 >,
			< 1267200000  730000  348 >,
			< 1344000000  740000  372 >,
			< 1420800000  750000  396 >,
			< 1497600000  760000  421 >,
			< 1574400000  770000  446 >,
			< 1651200000  780000  473 >,
			< 1728000000  790000  501 >,
			< 1804800000  805000  529 >,
			< 1881600000  820000  558 >,
			< 1958400000  835000  588 >,
			< 2035200000  850000  617 >,
			< 2112000000  865000  649 >,
			< 2150400000  880000  682 >,
			< 2188800000  880000  682 >,
			< 2265600000  895000  716 >,
			< 2342400000 910000  751 >,
			< 2419200000 925000  786 >,
			< 2457600000 930000  802 >;

		qcom,speed3-pvs10-bin-v1 =
			<          0       0    0 >,
			<  300000000  675000   76 >,
			<  345600000  675000   87 >,
			<  422400000  675000  106 >,
			<  499200000  675000  126 >,
			<  576000000  675000  147 >,
			<  652800000  675000  168 >,
			<  729600000  675000  189 >,
			<  806400000  675000  211 >,
			<  883200000  680000  233 >,
			<  960000000  685000  256 >,
			< 1036800000  695000  278 >,
			< 1113600000  705000  301 >,
			< 1190400000  715000  324 >,
			< 1267200000  725000  348 >,
			< 1344000000  735000  372 >,
			< 1420800000  745000  396 >,
			< 1497600000  755000  421 >,
			< 1574400000  765000  446 >,
			< 1651200000  775000  473 >,
			< 1728000000  785000  501 >,
			< 1804800000  795000  529 >,
			< 1881600000  810000  558 >,
			< 1958400000  825000  588 >,
			< 2035200000  840000  617 >,
			< 2112000000  855000  649 >,
			< 2150400000  870000  682 >,
			< 2188800000  870000  682 >,
			< 2265600000  885000  716 >,
			< 2342400000 900000  751 >,
			< 2419200000 915000  786 >,
			< 2457600000 920000  802 >;

		qcom,speed3-pvs11-bin-v1 =
			<          0       0    0 >,
			<  300000000  675000   76 >,
			<  345600000  675000   87 >,
			<  422400000  675000  106 >,
			<  499200000  675000  126 >,
			<  576000000  675000  147 >,
			<  652800000  675000  168 >,
			<  729600000  675000  189 >,
			<  806400000  675000  211 >,
			<  883200000  675000  233 >,
			<  960000000  680000  256 >,
			< 1036800000  690000  278 >,
			< 1113600000  700000  301 >,
			< 1190400000  710000  324 >,
			< 1267200000  720000  348 >,
			< 1344000000  730000  372 >,
			< 1420800000  740000  396 >,
			< 1497600000  750000  421 >,
			< 1574400000  760000  446 >,
			< 1651200000  770000  473 >,
			< 1728000000  780000  501 >,
			< 1804800000  790000  529 >,
			< 1881600000  800000  558 >,
			< 1958400000  815000  588 >,
			< 2035200000  830000  617 >,
			< 2112000000  845000  649 >,
			< 2150400000  860000  682 >,
			< 2188800000  860000  682 >,
			< 2265600000  875000  716 >,
			< 2342400000  890000  751 >,
			< 2419200000 905000  786 >,
			< 2457600000 910000  802 >;

		qcom,speed3-pvs12-bin-v1 =
			<          0       0    0 >,
			<  300000000  675000   76 >,
			<  345600000  675000   87 >,
			<  422400000  675000  106 >,
			<  499200000  675000  126 >,
			<  576000000  675000  147 >,
			<  652800000  675000  168 >,
			<  729600000  675000  189 >,
			<  806400000  675000  211 >,
			<  883200000  675000  233 >,
			<  960000000  680000  256 >,
			< 1036800000  685000  278 >,
			< 1113600000  695000  301 >,
			< 1190400000  705000  324 >,
			< 1267200000  715000  348 >,
			< 1344000000  725000  372 >,
			< 1420800000  735000  396 >,
			< 1497600000  745000  421 >,
			< 1574400000  755000  446 >,
			< 1651200000  765000  473 >,
			< 1728000000  775000  501 >,
			< 1804800000  785000  529 >,
			< 1881600000  795000  558 >,
			< 1958400000  805000  588 >,
			< 2035200000  820000  617 >,
			< 2112000000  835000  649 >,
			< 2150400000  850000  682 >,
			< 2188800000  850000  682 >,
			< 2265600000  865000  716 >,
			< 2342400000  880000  751 >,
			< 2419200000  895000  786 >,
			< 2457600000 900000  802 >;

		qcom,speed3-pvs13-bin-v1 =
			<          0       0    0 >,
			<  300000000  675000   76 >,
			<  345600000  675000   87 >,
			<  422400000  675000  106 >,
			<  499200000  675000  126 >,
			<  576000000  675000  147 >,
			<  652800000  675000  168 >,
			<  729600000  675000  189 >,
			<  806400000  675000  211 >,
			<  883200000  675000  233 >,
			<  960000000  675000  256 >,
			< 1036800000  680000  278 >,
			< 1113600000  690000  301 >,
			< 1190400000  700000  324 >,
			< 1267200000  710000  348 >,
			< 1344000000  720000  372 >,
			< 1420800000  730000  396 >,
			< 1497600000  740000  421 >,
			< 1574400000  750000  446 >,
			< 1651200000  760000  473 >,
			< 1728000000  770000  501 >,
			< 1804800000  780000  529 >,
			< 1881600000  790000  558 >,
			< 1958400000  800000  588 >,
			< 2035200000  810000  617 >,
			< 2112000000  825000  649 >,
			< 2150400000  840000  682 >,
			< 2188800000  840000  682 >,
			< 2265600000  855000  716 >,
			< 2342400000  870000  751 >,
			< 2419200000  885000  786 >,
			< 2457600000  890000  802 >;

		qcom,speed3-pvs14-bin-v1 =
			<          0       0    0 >,
			<  300000000  650000   76 >,
			<  345600000  650000   87 >,
			<  422400000  650000  106 >,
			<  499200000  650000  126 >,
			<  576000000  650000  147 >,
			<  652800000  650000  168 >,
			<  729600000  650000  189 >,
			<  806400000  650000  211 >,
			<  883200000  655000  233 >,
			<  960000000  665000  256 >,
			< 1036800000  675000  278 >,
			< 1113600000  685000  301 >,
			< 1190400000  695000  324 >,
			< 1267200000  705000  348 >,
			< 1344000000  715000  372 >,
			< 1420800000  725000  396 >,
			< 1497600000  735000  421 >,
			< 1574400000  745000  446 >,
			< 1651200000  755000  473 >,
			< 1728000000  765000  501 >,
			< 1804800000  775000  529 >,
			< 1881600000  785000  558 >,
			< 1958400000  795000  588 >,
			< 2035200000  805000  617 >,
			< 2112000000  815000  649 >,
			< 2150400000  830000  682 >,
			< 2188800000  830000  682 >,
			< 2265600000  845000  716 >,
			< 2342400000  860000  751 >,
			< 2419200000  875000  786 >,
			< 2457600000  880000  802 >;

		qcom,speed3-pvs15-bin-v1 =
			<          0       0    0 >,
			<  300000000  650000   76 >,
			<  345600000  650000   87 >,
			<  422400000  650000  106 >,
			<  499200000  650000  126 >,
			<  576000000  650000  147 >,
			<  652800000  650000  168 >,
			<  729600000  650000  189 >,
			<  806400000  650000  211 >,
			<  883200000  655000  233 >,
			<  960000000  660000  256 >,
			< 1036800000  670000  278 >,
			< 1113600000  680000  301 >,
			< 1190400000  690000  324 >,
			< 1267200000  700000  348 >,
			< 1344000000  710000  372 >,
			< 1420800000  720000  396 >,
			< 1497600000  730000  421 >,
			< 1574400000  740000  446 >,
			< 1651200000  750000  473 >,
			< 1728000000  760000  501 >,
			< 1804800000  770000  529 >,
			< 1881600000  780000  558 >,
			< 1958400000  790000  588 >,
			< 2035200000  800000  617 >,
			< 2112000000  810000  649 >,
			< 2150400000  820000  682 >,
			< 2188800000  820000  682 >,
			< 2265600000  835000  716 >,
			< 2342400000  850000  751 >,
			< 2419200000  865000  786 >,
			< 2457600000  870000  802 >;
	};

	i2c@f9928000 { /* BLSP-1 QUP-6 */
		cell-index = <3>;
		compatible = "qcom,i2c-qup";
		reg = <0xf9928000 0x1000>;
		#address-cells = <1>;
		#size-cells = <0>;
		reg-names = "qup_phys_addr";
		interrupts = <0 100 0>;
		interrupt-names = "qup_err_intr";
		qcom,i2c-bus-freq = <400000>;
		qcom,i2c-src-freq = <19200000>;
		qcom,sda-gpio = <&msmgpio 29 0>;
		qcom,scl-gpio = <&msmgpio 30 0>;
		qcom,master-id = <86>;
	};
};

/* GPU overrides */
&msm_gpu {
	/* Updated chip ID */
	qcom,chipid = <0x03030002>;
	qcom,msm-bus,num-cases = <15>;
	qcom,initial-pwrlevel = <3>;

	/* Updated bus bandwidth requirements */
	qcom,msm-bus,vectors-KBps =
		/* Off */
		<26 512 0 0>, <89 604 0 0>,
		/* Sub-SVS / SVS */
		<26 512 1200000 2456000>, <89 604 0 3200000>,
		/* SVS */
		<26 512 1200000 2456000>, <89 604 0 3200000>,
		/* low Nominal / SVS */
		<26 512 0 3680000>, <89 604 0 3200000>,
		/* SVS / low Nominal */
		<26 512 1200000 2456000>, <89 604 0 5280000>,
		/* low Nominal / low Nominal */
		<26 512 0 3680000>, <89 604 0 5280000>,
		/* Nominal / low Nominal */
		<26 512 0 4912000>, <89 604 0 5280000>,
		/* low Nominal / Nominal */
		<26 512 0 3680000>, <89 604 0 6224000>,
		/* Nominal / Nominal */
		<26 512 0 4912000>, <89 604 0 6224000>,
		/* low Turbo / Nominal */
		<26 512 0 6400000>, <89 604 0 6224000>,
		/* Nominal / low Turbo */
		<26 512 0 4912000>, <89 604 0 7398000>,
		/* low Turbo / low Turbo */
		<26 512 0 6400000>, <89 604 0 7398000>,
		/* Turbo / low Turbo */
		<26 512 0 7464000>, <89 604 0 7398000>,
		/* Nominal / Turbo */
		<26 512 0 4912000>, <89 604 0 9248000>,
		/* Turbo / Turbo */
		<26 512 0 7464000>, <89 604 0 9248000>;

       qcom,gpu-pwrlevels {
               #address-cells = <1>;
               #size-cells = <0>;

               compatible = "qcom,gpu-pwrlevels";

               qcom,gpu-pwrlevel@0 {
                       reg = <0>;
                       qcom,gpu-freq = <578000000>;
                       qcom,bus-freq = <14>;
                       qcom,io-fraction = <101>;
               };

               qcom,gpu-pwrlevel@1 {
                       reg = <1>;
                       qcom,gpu-freq = <462400000>;
                       qcom,bus-freq = <11>;
                       qcom,io-fraction = <101>;
               };

               qcom,gpu-pwrlevel@2 {
                       reg = <2>;
                       qcom,gpu-freq = <389000000>;
                       qcom,bus-freq = <8>;
                       qcom,io-fraction = <101>;
               };

               qcom,gpu-pwrlevel@3 {
                       reg = <3>;
                       qcom,gpu-freq = <330000000>;
                       qcom,bus-freq = <5>;
                       qcom,io-fraction = <101>;
               };

               qcom,gpu-pwrlevel@4 {
                       reg = <4>;
                       qcom,gpu-freq = <200000000>;
                       qcom,bus-freq = <2>;
                       qcom,io-fraction = <101>;
               };

               qcom,gpu-pwrlevel@5 {
                       reg = <5>;
                       qcom,gpu-freq = <27000000>;
                       qcom,bus-freq = <0>;
                       qcom,io-fraction = <101>;
               };
       };
};

&mdss_mdp {
	qcom,vbif-settings = <0x0004 0x00000001>;

	qcom,mdss-wb-off = <0x00011100 0x00011500
			    0x00011900 0x00011D00 0x00012100>;
	qcom,mdss-intf-off = <0x00012500 0x00012700
			      0x00012900 0x00012b00>;
	qcom,mdss-pingpong-off = <0x00012D00 0x00012E00 0x00012F00>;
	qcom,mdss-has-bwc;
	qcom,mdss-has-decimation;
	qcom,mdss-ad-off = <0x0013100 0x00013300>;
};

&mdss_hdmi_tx {
	reg =	<0xfd922100 0x370>,
		<0xfd922500 0x7C>,
		<0xfc4b8000 0x60F0>;
	reg-names = "core_physical", "phy_physical", "qfprom_physical";
};

&msm_vidc {
	qcom,vidc-ns-map = <0x40000000 0x40000000>;
	qcom,load-freq-tbl = <1036800 465000000>,
		<783360 465000000>,
		<489600 266670000>,
		<244800 133330000>;
	qcom,reg-presets = <0x80004 0x1>,
		<0x80070 0x11FFF>,
		<0x80074 0xA4>,
		<0x800A8 0x1FFF>,
		<0x80124 0x3>,
		<0xE0020 0x5555556>,
		<0xE0024 0x0>;
	qcom,bus-ports = <1>;
	qcom,enc-ocmem-ab-ib = <0 0>,
		<138000 1034000>,
		<414000 1034000>,
		<940000 1034000>,
		<1880000 2068000>,
		<3008000 3309000>,
		<3760000 4136000>,
		<4468000 2457000>;
	qcom,dec-ocmem-ab-ib = <0 0>,
		<176000 519000>,
		<456000 519000>,
		<864000 629000>,
		<1728000 1038000>,
		<2766000 1661000>,
		<3456000 2076000>,
		<3662000 2198000>;
	qcom,enc-ddr-ab-ib = <0 0>,
		<120000 302000>,
		<364000 302000>,
		<804000 302000>,
		<1608000 604000>,
		<2576000 967000>,
		<4680000 1404000>,
		<4988000 1496000>;
	qcom,dec-ddr-ab-ib = <0 0>,
		<208000 303000>,
		<536000 1600000>,
		<1012000 1600000>,
		<2024000 1600000>,
		<3240000 1600000>,
		<4048000 1600000>,
		<4264000 1600000>;
	qcom,max-hw-load = <1281600>; /* max(4k X 2304 @ 24, 4k X 2160 @ 30) + 1080p @ 30 */
	qcom,buffer-type-tz-usage-table = <0x241 0x1>,
					<0x106 0x2>,
					<0x480 0x3>;
	qcom,vidc-iommu-domains {
		qcom,domain-ns {
			qcom,vidc-domain-phandle = <&venus_domain_ns>;
			qcom,vidc-partition-buffer-types = <0x7ff>,
							<0x800>;
		};
		qcom,domain-sec-bs {
			qcom,vidc-domain-phandle = <&venus_domain_sec_bitstream>;
			qcom,vidc-partition-buffer-types = <0x241>;
		};
		qcom,domain-sec-px {
			qcom,vidc-domain-phandle = <&venus_domain_sec_pixel>;
			qcom,vidc-partition-buffer-types = <0x106>;
		};
		qcom,domain-sec-np {
			qcom,vidc-domain-phandle = <&venus_domain_sec_non_pixel>;
			qcom,vidc-partition-buffer-types = <0x480>;
		};
	};
};

&memory_hole {
	qcom,memblock-remove = <0x05a00000 0x7800000
				0x0fa00000 0x500000>; /* Address and size of the hole */
};

&gdsc_venus {
	qcom,skip-logic-collapse;
	qcom,retain-periph;
	qcom,retain-mem;
};

&sdhc_1 {
	reg = <0xf9824900 0x1a0>, <0xf9824000 0x800>;

	qcom,clk-rates = <400000 20000000 25000000 50000000 100000000 192000000 384000000>;
	qcom,bus-speed-mode = "HS400_1p8v", "HS200_1p8v", "DDR_1p8v";
};
